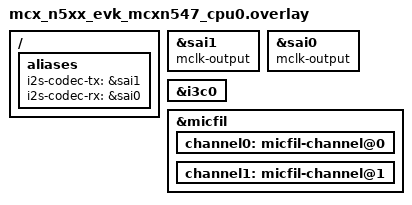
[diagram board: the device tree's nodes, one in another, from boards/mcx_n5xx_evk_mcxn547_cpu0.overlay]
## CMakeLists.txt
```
cmake_minimum_required (VERSION 3.20.0)
find_package(Zephyr REQUIRED HINTS $ENV{ZEPHYR_BASE})
project(dmic_i2s)

FILE(GLOB app_sources src/*.c)
target_sources(app PRIVATE ${app_sources})
```

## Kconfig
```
# Copyright 2026 NXP
# SPDX-License-Identifier: Apache-2.0

source "Kconfig.zephyr"

choice SAMPLE_AUDIO_SOURCE
	prompt "Capture source the pipeline reads from"
	default SAMPLE_AUDIO_SOURCE_DMIC
	help
	  Which source element the pipeline is built with. The rest of the
	  pipeline is the same either way.

config SAMPLE_AUDIO_SOURCE_DMIC
	bool "Digital microphone"
	help
	  Capture from a PDM microphone through the DMIC API. Requires a
	  dmic_dev node label.

config SAMPLE_AUDIO_SOURCE_I2S
	bool "I2S receiver"
	help
	  Capture from an I2S receiver, either a microphone that outputs I2S
	  directly or a codec's ADC. Requires an i2s-codec-rx alias, and an
	  audio-codec-capture alias when the capture path runs through a codec
	  that has to be configured.

endchoice

config SAMPLE_AUDIO_GAIN_PERCENT
	int "Gain applied by the pipeline (percent)"
	default 90
	range 0 1000
	help
	  Gain the pipeline's gain element applies, as a percentage: 0 mutes,
	  100 is unity and 1000 amplifies ten times. Values above 100 can clip,
	  in which case samples saturate at full scale.

config USE_I2S_TARGET_CODEC_CONTROLLER
	bool "I2S BCK is generated by a selected codec device"
	help
	  If selected, the I2S selected peripheral will be configured to consume
	  (receive) the I2S BCK and WS signals and the codec will be configured
	  to generate those. If not selected, the I2S peripheral will generate
	  them and the codec will be expected to consume them.
```

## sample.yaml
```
sample:
  name: Audio loopback pipeline sample

tests:
  sample.mp.audio_loopback:
    tags:
      - audio
      - samples
    platform_allow:
      - mimxrt685_evk/mimxrt685s/cm33
      - mimxrt1170_evk@B/mimxrt1176/cm7
      - mimxrt595_evk/mimxrt595s/cm33
      - mcx_n5xx_evk/mcxn547/cpu0
      - native_sim/native/64
    harness: console
    harness_config:
      type: one_line
      regex:
        - "Capture started"

  # Run the pipeline headless on native_sim and compare its output against the
  # input scaled by the configured gain. Unity gain and a gain above unity are
  # both covered, the latter exercising saturation.
  sample.mp.audio_loopback.output.unity_gain:
    tags:
      - audio
      - samples
    platform_allow:
      - native_sim/native/64
    integration_platforms:
      - native_sim/native/64
    extra_configs:
      - CONFIG_SAMPLE_AUDIO_GAIN_PERCENT=100
    harness: pytest
    harness_config:
      pytest_root:
        - "pytest/test_pipeline.py"

  sample.mp.audio_loopback.output.amplified:
    tags:
      - audio
      - samples
    platform_allow:
      - native_sim/native/64
    integration_platforms:
      - native_sim/native/64
    extra_configs:
      - CONFIG_SAMPLE_AUDIO_GAIN_PERCENT=200
    harness: pytest
    harness_config:
      pytest_root:
        - "pytest/test_pipeline.py"

  # The same pipeline reading from an I2S receiver instead of a DMIC. Built for
  # every board here that has an i2s-codec-rx alias.
  sample.mp.audio_loopback.i2s_source:
    tags:
      - audio
      - samples
    platform_allow:
      - mimxrt685_evk/mimxrt685s/cm33
      - mimxrt595_evk/mimxrt595s/cm33
      - mcx_n5xx_evk/mcxn547/cpu0
      - native_sim/native/64
    integration_platforms:
      - native_sim/native/64
    extra_configs:
      - CONFIG_SAMPLE_AUDIO_SOURCE_I2S=y
    harness: console
    harness_config:
      type: one_line
      regex:
        - "Capture started"

  sample.mp.audio_loopback.i2s_source.output:
    tags:
      - audio
      - samples
    platform_allow:
      - native_sim/native/64
    integration_platforms:
      - native_sim/native/64
    extra_configs:
      - CONFIG_SAMPLE_AUDIO_SOURCE_I2S=y
      - CONFIG_SAMPLE_AUDIO_GAIN_PERCENT=200
    harness: pytest
    harness_config:
      pytest_root:
        - "pytest/test_pipeline.py"
```

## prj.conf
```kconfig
CONFIG_LOG=y

CONFIG_HEAP_MEM_POOL_SIZE=25000
CONFIG_MAIN_STACK_SIZE=4096

CONFIG_MP=y
CONFIG_MP_BASE=y
CONFIG_MP_BASE_CAPSFILTER=y
CONFIG_MP_AUD=y

CONFIG_AUDIO_DMIC=y
CONFIG_AUDIO_CODEC=y

CONFIG_I2S=y

CONFIG_SHELL=y
CONFIG_DEVICE_SHELL=y
```

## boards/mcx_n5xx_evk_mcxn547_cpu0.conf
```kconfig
# Copyright 2026 NXP
#
# SPDX-License-Identifier: Apache-2.0

CONFIG_I3C=y
CONFIG_AUDIO_CODEC=y

CONFIG_MP_AUD_BUFFER_POOL_SZ_MAX=4096
CONFIG_MP_AUD_BUFFER_POOL_NUM_MAX=8

CONFIG_DMA_TCD_QUEUE_SIZE=4
CONFIG_AUDIO_CODEC_DA7212=y
```

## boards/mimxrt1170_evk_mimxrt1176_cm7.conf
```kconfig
#
# Copyright 2026 NXP
#
# SPDX-License-Identifier: Apache-2.0
#

CONFIG_I3C=y
CONFIG_AUDIO_CODEC=y

CONFIG_AUDIO_CODEC_WM8962=y

CONFIG_MP_AUD_BUFFER_POOL_SZ_MAX=4096
CONFIG_MP_AUD_BUFFER_POOL_NUM_MAX=8

CONFIG_DMA_TCD_QUEUE_SIZE=4
```

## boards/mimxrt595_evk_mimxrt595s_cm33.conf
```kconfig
#
# Copyright 2026 NXP
#
# SPDX-License-Identifier: Apache-2.0
#

CONFIG_I3C=y
CONFIG_AUDIO_CODEC=y

CONFIG_MP_AUD_BUFFER_POOL_SZ_MAX=4096
CONFIG_MP_AUD_BUFFER_POOL_NUM_MAX=8

CONFIG_USE_I2S_TARGET_CODEC_CONTROLLER=y

# The I2S codec sink primes AUD_I2S_SINK_START_PRIME (3) writes into the I2S TX
# queue before issuing I2S_TRIGGER_START. The TX in_queue must therefore be able
# to hold at least that many buffers, otherwise the priming writes block on a
# full queue, START never fires, and the shared buffer pool drains.
CONFIG_I2S_MCUX_FLEXCOMM_TX_BLOCK_COUNT=4
```

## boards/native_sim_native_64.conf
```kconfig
#
# Copyright 2026 NXP
#
# SPDX-License-Identifier: Apache-2.0
#

CONFIG_AUDIO_CODEC=y
CONFIG_AUDIO_CODEC_DUMMY=y
CONFIG_AUDIO_DMIC=y
CONFIG_AUDIO_DMIC_NATIVE_SIM=y
CONFIG_I2S=y
CONFIG_I2S_NATIVE_SIM=y

CONFIG_MP_AUD_BUFFER_POOL_SZ_MAX=4096
CONFIG_MP_AUD_BUFFER_POOL_NUM_MAX=8

CONFIG_I2S_NATIVE_SIM_TX_FILE_PATH="build/native_sim_audio_pipeline_tx.pcm"
```

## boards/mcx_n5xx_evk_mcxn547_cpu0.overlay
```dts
/*
 * Copyright 2026 NXP
 *
 * SPDX-License-Identifier: Apache-2.0
 */

/ {
	aliases {
		i2s-codec-tx = &sai1;
		i2s-codec-rx = &sai0;
	};
};

&sai1 {
	mclk-output;
};

&sai0 {
	mclk-output;
};

&i3c0 {
	status = "okay";
};

dmic_dev: &micfil {
	channel0: micfil-channel@0 {
		status = "okay";
	};

	channel1: micfil-channel@1 {
		status = "okay";
	};
};
```

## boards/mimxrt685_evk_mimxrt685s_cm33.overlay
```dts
/*
 * Copyright 2025 NXP
 *
 * SPDX-License-Identifier: Apache-2.0
 */

/ {
	aliases {
		i2s-codec-rx = &i2s0;
		/* one codec serves both directions on this board */
		audio-codec-capture = &audio_codec;
		i2s-codec-tx = &i2s1;
	};
};

&i3c0 {
	status = "okay";
};

&i2s0 {
	status = "okay";
};

&i2s1 {
	status = "okay";
};

dmic_dev: &dmic0 {
	status = "okay";
};
```

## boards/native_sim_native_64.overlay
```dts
/*
 * Copyright 2026 NXP
 *
 * SPDX-License-Identifier: Apache-2.0
 */

/ {
	aliases {
		i2s-codec-tx = &i2s_tx0;
		i2s-codec-rx = &i2s_rx0;
	};
};

dmic_dev: &dmic0 {
	status = "okay";
};

&i2s_tx0 {
	status = "okay";
};

&i2s_rx0 {
	status = "okay";
};

&audio_codec {
	status = "okay";
};
```

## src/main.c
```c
/*
 * Copyright 2025 NXP
 *
 * SPDX-License-Identifier: Apache-2.0
 */

#include <zephyr/kernel.h>
#include <zephyr/logging/log.h>

#include <zephyr/mp/mp.h>
#include <zephyr/mp/aud/mp_aud.h>
#include <zephyr/mp/aud/mp_aud_src.h>
#include <zephyr/mp/aud/mp_aud_i2s_codec_sink.h>
#include <zephyr/mp/aud/mp_aud_gain.h>
#include <zephyr/mp/aud/mp_aud_dmic_src.h>
#include <zephyr/mp/aud/mp_aud_buffer_pool.h>
#include <zephyr/mp/base/mp_capsfilter.h>

LOG_MODULE_REGISTER(main);

#define LOG_LEVEL LOG_LEVEL_DBG

/* Element IDs (values are arbitrary; only uniqueness within the pipeline matters) */
enum {
	PIPE_ID,
	DMIC_SRC_ID,
	CAPS_FILTER_ID,
	AUD_GAIN_ID,
	I2S_SINK_ID,
};

/*
 * WORKAROUND: Direct memory slab management in application code
 *
 * TODO: Normally, applications should not set this because they do not
 * need to know about the memory slab audio buffers implementation.
 *
 * The __nocache attribute ensures this memory is not cached, which is
 * required for DMA operations used by audio hardware.
 */
__nocache struct k_mem_slab mem_slab;

static struct mp_pipeline pipe;
static struct mp_aud_dmic_src source;
static struct mp_aud_gain gain;
static struct mp_aud_i2s_codec_sink sink;
static struct mp_caps_filter caps_filter;

int main(void)
{
	int gain_val = 90; /* Set gain to 90% (0.9x amplification) */
	int ret = 0;

	MP_ELEMENT_INIT(&pipe, mp_pipeline_init, PIPE_ID);
	MP_ELEMENT_INIT(&source, mp_aud_dmic_src_init, DMIC_SRC_ID);
	MP_ELEMENT_INIT(&gain, mp_aud_gain_init, AUD_GAIN_ID);
	MP_ELEMENT_INIT(&sink, mp_aud_i2s_codec_sink_init, I2S_SINK_ID);

	ret = mp_object_set_properties((struct mp_object *)&source, MP_PROP_AUD_SRC_SLAB_PTR,
				       &mem_slab, MP_PROP_LIST_END);
	if (ret < 0) {
		LOG_ERR("Failed to set properties for source element");
		goto err;
	}

	ret = mp_object_set_properties(
		(struct mp_object *)&sink, MP_PROP_AUD_SINK_SLAB_PTR, &mem_slab,
#if (defined(CONFIG_USE_I2S_TARGET_CODEC_CONTROLLER) && CONFIG_USE_I2S_TARGET_CODEC_CONTROLLER == 1)
		MP_PROP_AUD_SINK_CLK_ROLE, MP_AUD_I2S_TARGET_CODEC_CONTROLLER,
#endif
		MP_PROP_LIST_END);
	if (ret < 0) {
		LOG_ERR("Failed to set properties for sink element");
		goto err;
	}

	ret = mp_object_set_properties((struct mp_object *)&gain, MP_PROP_AUD_TRANSFORM_GAIN,
				       &gain_val, MP_PROP_LIST_END);
	if (ret < 0) {
		LOG_ERR("Failed to set properties for gain element");
		goto err;
	}

	/* Caps filter element */
	MP_ELEMENT_INIT(&caps_filter, mp_caps_filter_init, CAPS_FILTER_ID);

	uint32_t frame_interval = 10000; /* 10ms */
	struct mp_caps *caps =
		mp_caps_new(MP_MEDIA_AUDIO_PCM, MP_CAPS_FRAME_INTERVAL, MP_TYPE_UINT,
			    frame_interval, MP_CAPS_NUM_OF_CHANNEL, MP_TYPE_UINT, 2, MP_CAPS_END);

	if (caps == NULL) {
		LOG_ERR("Failed to create a caps");
		goto err;
	}

	ret = mp_object_set_properties((struct mp_object *)&caps_filter,
				       MP_PROP_BASE_CAPSFILTER_CAPS, caps, MP_PROP_LIST_END);
	mp_caps_unref(caps);
	if (ret < 0) {
		LOG_ERR("Failed to set properties for caps filter element");
		goto err;
	}

	/* clang-format off */
	/* Add elements to the pipeline - order does not matter */
	ret = mp_bin_add((struct mp_bin *)&pipe,
			(struct mp_element *)&source,
			IF_ENABLED(CONFIG_MP_BASE_CAPSFILTER, ((struct mp_element *)&caps_filter,))
			(struct mp_element *)&gain,
			(struct mp_element *)&sink, NULL);
	if (ret < 0) {
		LOG_ERR("Failed to add elements (%d)", ret);
		goto err;
	}

	/* Link elements together - order does matter */
	ret = mp_element_link((struct mp_element *)&source,
			IF_ENABLED(CONFIG_MP_BASE_CAPSFILTER, ((struct mp_element *)&caps_filter,))
			(struct mp_element *)&gain,
			(struct mp_element *)&sink, NULL);
	if (ret < 0) {
		LOG_ERR("Failed to link elements (%d)", ret);
		goto err;
	}
	/* clang-format on */

	/* Start playing */
	if (mp_element_set_state((struct mp_element *)&pipe, MP_STATE_PLAYING) !=
	    MP_STATE_CHANGE_SUCCESS) {
		LOG_ERR("Failed to start pipeline");
		goto err;
	}

	/* Handle message from the pipeline */
	struct mp_bus *bus = mp_element_get_bus((struct mp_element *)&pipe);
	struct mp_message msg;

	/* Wait until an Error or an EOS - blocking */
	mp_bus_pop_msg(bus, MP_MESSAGE_ERROR | MP_MESSAGE_EOS, &msg);

	switch (msg.type) {
	case MP_MESSAGE_ERROR:
		LOG_ERR("ERROR message from element %d", msg.origin->object.id);
		break;
	case MP_MESSAGE_EOS:
		LOG_INF("EOS message from element %d", msg.origin->object.id);
		break;
	default:
		LOG_ERR("Unexpected message from element %d", msg.origin->object.id);
		break;
	}

	/* Stop/Deinit the pipeline */
	(void)mp_element_set_state((struct mp_element *)&pipe, MP_STATE_READY);

	return 0;

err:
	LOG_ERR("Aborting sample");
	return 0;
}
```
